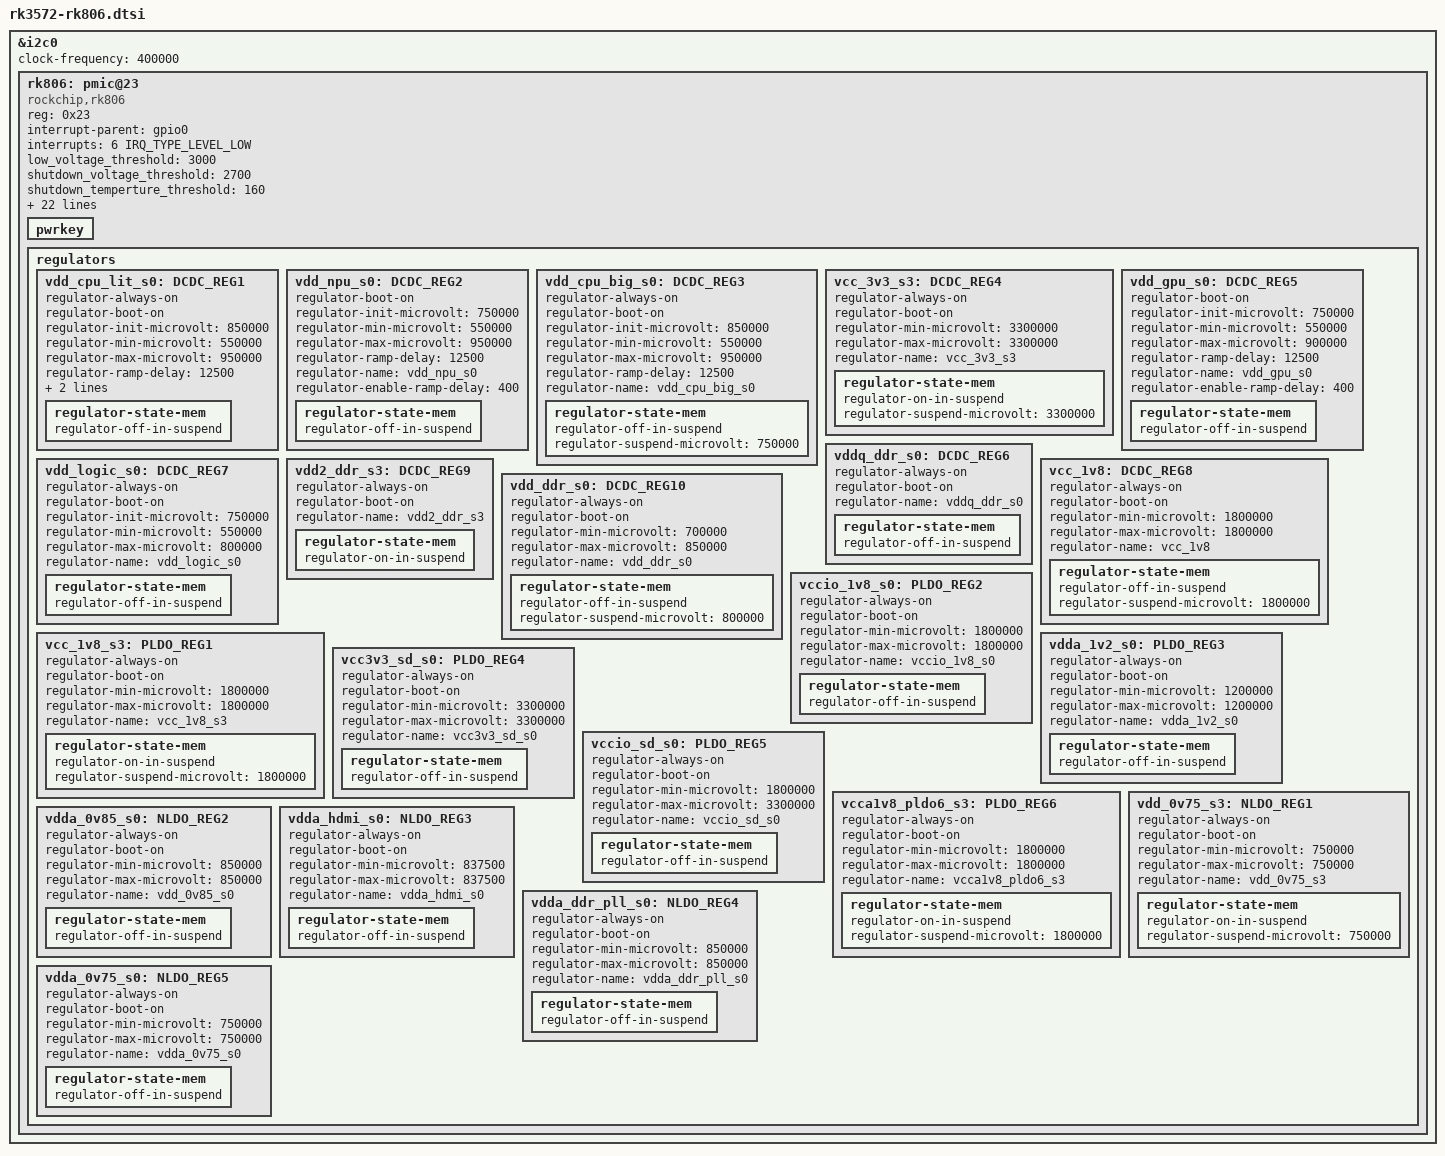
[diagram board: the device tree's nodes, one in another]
// SPDX-License-Identifier: (GPL-2.0+ OR MIT)
/*
 * Copyright (c) 2025 Rockchip Electronics Co., Ltd.
 *
 */

#include <dt-bindings/gpio/gpio.h>
#include <dt-bindings/pinctrl/rockchip.h>

&i2c0 {
	status = "okay";
	clock-frequency = <400000>;

	rk806: pmic@23 {
		compatible = "rockchip,rk806";
		reg = <0x23>;

		interrupt-parent = <&gpio0>;
		interrupts = <6 IRQ_TYPE_LEVEL_LOW>;

		/* 2800mv-3500mv */
		low_voltage_threshold = <3000>;
		/* 2700mv-3400mv */
		shutdown_voltage_threshold = <2700>;
		/* 140 160 */
		shutdown_temperture_threshold = <160>;
		hotdie_temperture_threshold = <115>;
		/* shutdown sequence */
		shutdown-sequence = <2 2 2 0 2 0 2 1 1 2
					2 2 2 2 2
					1 0 1 0 0 2>;

		/* low power forced shutdown sequence */
		vb-shutdown-sequence = <2 2 2 0 2 0 2 1 1 2
					2 2 2 2 2
					1 0 1 0 0 2>;

		/*
		 * 0: restart PMU;
		 * 1: reset all the power off reset registers,
		 *    forcing the state to switch to ACTIVE mode;
		 * 2: Reset all the power off reset registers,
		 *    forcing the state to switch to ACTIVE mode,
		 *    and simultaneously pull down the RESETB PIN for 5mS before releasing
		 */
		pmic-reset-func = <1>;
		/* buck5 external feedback resister disable */
		buck5-feedback-disable;

		vcc1-supply = <&vcc5v0_sys_s5>;
		vcc2-supply = <&vcc5v0_sys_s5>;
		vcc3-supply = <&vcc5v0_sys_s5>;
		vcc4-supply = <&vcc5v0_sys_s5>;
		vcc5-supply = <&vcc5v0_sys_s5>;
		vcc6-supply = <&vcc5v0_sys_s5>;
		vcc7-supply = <&vcc5v0_sys_s5>;
		vcc8-supply = <&vcc5v0_sys_s5>;
		vcc9-supply = <&vcc5v0_sys_s5>;
		vcc10-supply = <&vcc5v0_sys_s5>;
		vcc11-supply = <&vcc_ldo_s3>;
		vcc12-supply = <&vcc5v0_sys_s5>;
		vcc13-supply = <&vcc_ldo_s3>;
		vcc14-supply = <&vcc_ldo_s3>;
		vcca-supply = <&vcc5v0_sys_s5>;

		pwrkey {
			status = "okay";
		};

		regulators {
			vdd_cpu_lit_s0: DCDC_REG1 {
				regulator-always-on;
				regulator-boot-on;
				regulator-init-microvolt = <850000>;
				regulator-min-microvolt = <550000>;
				regulator-max-microvolt = <950000>;
				regulator-ramp-delay = <12500>;
				regulator-name = "vdd_cpu_lit_s0";
				regulator-enable-ramp-delay = <400>;
				regulator-state-mem {
					regulator-off-in-suspend;
				};
			};

			vdd_npu_s0: DCDC_REG2 {
				regulator-boot-on;
				regulator-init-microvolt = <750000>;
				regulator-min-microvolt = <550000>;
				regulator-max-microvolt = <950000>;
				regulator-ramp-delay = <12500>;
				regulator-name = "vdd_npu_s0";
				regulator-enable-ramp-delay = <400>;
				regulator-state-mem {
					regulator-off-in-suspend;
				};
			};

			vdd_cpu_big_s0: DCDC_REG3 {
				regulator-always-on;
				regulator-boot-on;
				regulator-init-microvolt = <850000>;
				regulator-min-microvolt = <550000>;
				regulator-max-microvolt = <950000>;
				regulator-ramp-delay = <12500>;
				regulator-name = "vdd_cpu_big_s0";
				regulator-state-mem {
					regulator-off-in-suspend;
					regulator-suspend-microvolt = <750000>;
				};
			};

			vcc_3v3_s3: DCDC_REG4 {
				regulator-always-on;
				regulator-boot-on;
				regulator-min-microvolt = <3300000>;
				regulator-max-microvolt = <3300000>;
				regulator-name = "vcc_3v3_s3";
				regulator-state-mem {
					regulator-on-in-suspend;
					regulator-suspend-microvolt = <3300000>;
				};
			};

			vdd_gpu_s0: DCDC_REG5 {
				regulator-boot-on;
				regulator-init-microvolt = <750000>;
				regulator-min-microvolt = <550000>;
				regulator-max-microvolt = <900000>;
				regulator-ramp-delay = <12500>;
				regulator-name = "vdd_gpu_s0";
				regulator-enable-ramp-delay = <400>;
				regulator-state-mem {
					regulator-off-in-suspend;
				};
			};

			vddq_ddr_s0: DCDC_REG6 {
				regulator-always-on;
				regulator-boot-on;
				regulator-name = "vddq_ddr_s0";
				regulator-state-mem {
					regulator-off-in-suspend;
				};
			};

			vdd_logic_s0: DCDC_REG7 {
				regulator-always-on;
				regulator-boot-on;
				regulator-init-microvolt = <750000>;
				regulator-min-microvolt = <550000>;
				regulator-max-microvolt = <800000>;
				regulator-name = "vdd_logic_s0";
				regulator-state-mem {
					regulator-off-in-suspend;
				};
			};

			vcc_1v8: DCDC_REG8 {
				regulator-always-on;
				regulator-boot-on;
				regulator-min-microvolt = <1800000>;
				regulator-max-microvolt = <1800000>;
				regulator-name = "vcc_1v8";
				regulator-state-mem {
					regulator-off-in-suspend;
					regulator-suspend-microvolt = <1800000>;
				};
			};

			vdd2_ddr_s3: DCDC_REG9 {
				regulator-always-on;
				regulator-boot-on;
				regulator-name = "vdd2_ddr_s3";
				regulator-state-mem {
					regulator-on-in-suspend;
				};
			};

			vdd_ddr_s0: DCDC_REG10 {
				regulator-always-on;
				regulator-boot-on;
				regulator-min-microvolt = <700000>;
				regulator-max-microvolt = <850000>;
				regulator-name = "vdd_ddr_s0";
				regulator-state-mem {
					regulator-off-in-suspend;
					regulator-suspend-microvolt = <800000>;
				};
			};

			vcc_1v8_s3: PLDO_REG1 {
				regulator-always-on;
				regulator-boot-on;
				regulator-min-microvolt = <1800000>;
				regulator-max-microvolt = <1800000>;
				regulator-name = "vcc_1v8_s3";
				regulator-state-mem {
					regulator-on-in-suspend;
					regulator-suspend-microvolt = <1800000>;
				};
			};

			vccio_1v8_s0: PLDO_REG2 {
				regulator-always-on;
				regulator-boot-on;
				regulator-min-microvolt = <1800000>;
				regulator-max-microvolt = <1800000>;
				regulator-name = "vccio_1v8_s0";
				regulator-state-mem {
					regulator-off-in-suspend;
				};
			};

			vdda_1v2_s0: PLDO_REG3 {
				regulator-always-on;
				regulator-boot-on;
				regulator-min-microvolt = <1200000>;
				regulator-max-microvolt = <1200000>;
				regulator-name = "vdda_1v2_s0";
				regulator-state-mem {
					regulator-off-in-suspend;
				};
			};

			vcc3v3_sd_s0: PLDO_REG4 {
				regulator-always-on;
				regulator-boot-on;
				regulator-min-microvolt = <3300000>;
				regulator-max-microvolt = <3300000>;
				regulator-name = "vcc3v3_sd_s0";
				regulator-state-mem {
					regulator-off-in-suspend;
				};
			};

			vccio_sd_s0: PLDO_REG5 {
				regulator-always-on;
				regulator-boot-on;
				regulator-min-microvolt = <1800000>;
				regulator-max-microvolt = <3300000>;
				regulator-name = "vccio_sd_s0";
				regulator-state-mem {
					regulator-off-in-suspend;
				};
			};

			vcca1v8_pldo6_s3: PLDO_REG6 {
				regulator-always-on;
				regulator-boot-on;
				regulator-min-microvolt = <1800000>;
				regulator-max-microvolt = <1800000>;
				regulator-name = "vcca1v8_pldo6_s3";
				regulator-state-mem {
					regulator-on-in-suspend;
					regulator-suspend-microvolt = <1800000>;
				};
			};

			vdd_0v75_s3: NLDO_REG1 {
				regulator-always-on;
				regulator-boot-on;
				regulator-min-microvolt = <750000>;
				regulator-max-microvolt = <750000>;
				regulator-name = "vdd_0v75_s3";
				regulator-state-mem {
					regulator-on-in-suspend;
					regulator-suspend-microvolt = <750000>;
				};
			};

			vdda_0v85_s0: NLDO_REG2 {
				regulator-always-on;
				regulator-boot-on;
				regulator-min-microvolt = <850000>;
				regulator-max-microvolt = <850000>;
				regulator-name = "vdd_0v85_s0";
				regulator-state-mem {
					regulator-off-in-suspend;
				};
			};

			vdda_hdmi_s0: NLDO_REG3 {
				regulator-always-on;
				regulator-boot-on;
				regulator-min-microvolt = <837500>;
				regulator-max-microvolt = <837500>;
				regulator-name = "vdda_hdmi_s0";
				regulator-state-mem {
					regulator-off-in-suspend;
				};
			};

			vdda_ddr_pll_s0: NLDO_REG4 {
				regulator-always-on;
				regulator-boot-on;
				regulator-min-microvolt = <850000>;
				regulator-max-microvolt = <850000>;
				regulator-name = "vdda_ddr_pll_s0";
				regulator-state-mem {
					regulator-off-in-suspend;
				};
			};

			vdda_0v75_s0: NLDO_REG5 {
				regulator-always-on;
				regulator-boot-on;
				regulator-min-microvolt = <750000>;
				regulator-max-microvolt = <750000>;
				regulator-name = "vdda_0v75_s0";
				regulator-state-mem {
					regulator-off-in-suspend;
				};
			};
		};
	};
};
